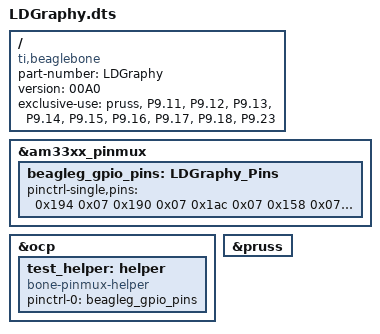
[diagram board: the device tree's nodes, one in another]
/*
 * Based on github.com/jadonk/validation-scripts/tree/master/test-capemgr
 * Copyright (C) 2012 Texas Instruments Incorporated - http://www.ti.com/
 *
 * This is part of LDGraphy which is free software; you can redistribute it
 * and/or modify it under the terms of the GNU General Purpose License Version 2
 * as published by the Free Software Foundation
 *
 * To create the binary representation that the device manager can handle, run
 *   make LDGraphy-00A0.dtbo
 * (The binary is checked into github, so this is only needed if you are
 *  modifying this file)
 */

/dts-v1/;
/plugin/;

/{
    compatible = "ti,beaglebone", "ti,beaglebone-black", "ti,beaglebone-green";
    part-number = "LDGraphy";
    version = "00A0";

    exclusive-use = "pruss",  // Programmable realtime unit
                    "P9.11", "P9.12", "P9.13", "P9.14", "P9.15", "P9.16",
                    "P9.17", "P9.18", "P9.23";

    fragment@0 {
        target = <&am33xx_pinmux>;
        __overlay__ {
            beagleg_gpio_pins: LDGraphy_Pins {
                pinctrl-single,pins = <
		    /* Laser Data */
		    0x194 0x07 /* GPIO_3[15] ; P9.29, IC_HB_PWM1, pulldown */
            0x190 0x07 /* GPIO_3[14] ; P9.31, IC_HB_PWM2, pulldown */
		    

            /* Polygon */
            0x1ac 0x07 /* GPIO_3[21] ; P9.25, Polygon Enable, pulldown */
            0x158 0x07 /* GPIO_0[4]  ; P9.18, Polygon Ready, pulldown */
            0x1a4 0x07 /* GPIO_1[19] ; P9.27, Polygon PWM, pulldown */

		    /* X-Direction */
		    0x078 0x07 /* GPIO_1[28]; P9.12, X-Dir, pulldown    */
		    0x19c 0x07 /* GPIO_3[17]; P9.28, X-Step, pulldown   */
            0x040 0x07 /* GPIO_1[16]; P9.15, X-Enable, pulldown */

            /* Y-Direction */
            0x178 0x07 /* GPIO_0[12]; P9.20, Y-Dir, pulldown    */
		    0x198 0x07 /* GPIO_3[16]; P9.30, Y-Step, pulldown   */
            0x1ac 0x07 /* GPIO_3[21]; P9.25, Y-Enable, pulldown */

		    /* Input */
		    0x1b4 0x3F /* GPIO_0[20]; P9.41, Hsync AKA photodiode input, Pullup disable */

                >;
            };
        };
    };

    fragment@1 {
        target = <&ocp>;
        __overlay__ {
            test_helper: helper {
                compatible = "bone-pinmux-helper";
                pinctrl-names = "default";
                pinctrl-0 = <&beagleg_gpio_pins>;
                status = "okay";
            };
        };
    };

   fragment@2{
        target = <&pruss>;
        __overlay__ {
            status = "okay";
        };
   };
};
